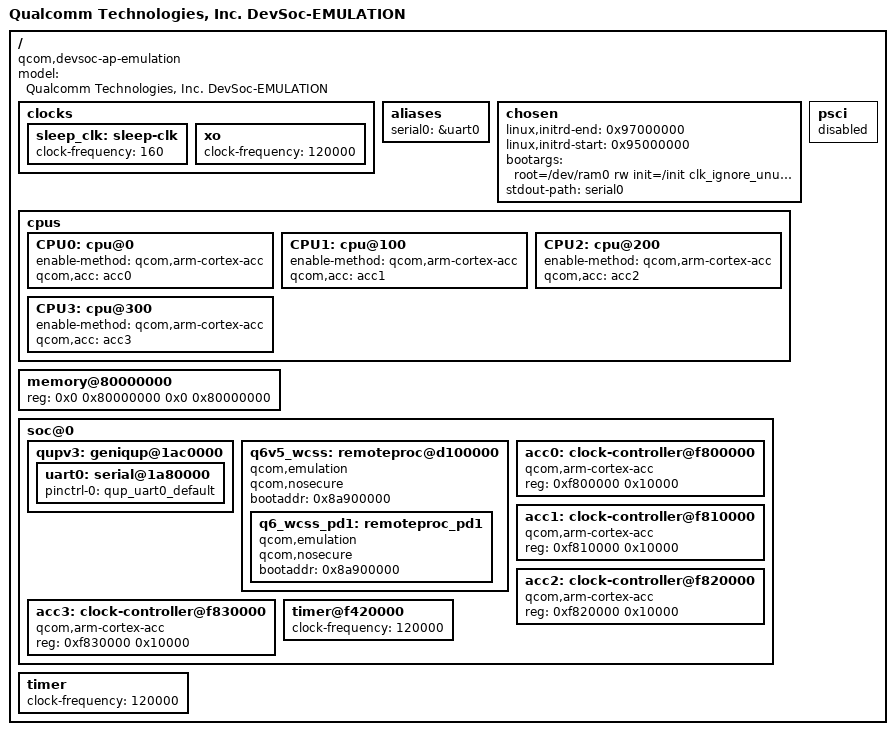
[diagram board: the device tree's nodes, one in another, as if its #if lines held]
// SPDX-License-Identifier: (GPL-2.0+ OR BSD-3-Clause)
/*
 * Dev SoC Emulation SSOC device tree source
 *
 * Copyright (c) 2020-2021 The Linux Foundation. All rights reserved.
 * Copyright (c) 2022-2023 Qualcomm Innovation Center, Inc. All rights reserved.
 */

/dts-v1/;

#include "devsoc.dtsi"

/ {
	model = "Qualcomm Technologies, Inc. DevSoc-EMULATION";
	compatible = "qcom,devsoc-ap-emulation", "qcom,devsoc";

	/*Timer freq for rumi = timer freq / 200*/
	clocks {
		sleep_clk: sleep-clk {
			clock-frequency = <160>;
		};

		xo: xo {
			clock-frequency = <120000>;
		};
	};

	aliases {
		serial0 = &uart0;
	};

	chosen {
		linux,initrd-end = <0x97000000>;
		linux,initrd-start = <0x95000000>;
		bootargs = "root=/dev/ram0 rw init=/init clk_ignore_unused maxcpus=2";
		stdout-path = "serial0";
	};

	cpus: cpus {
		CPU0: cpu@0 {
			enable-method = "qcom,arm-cortex-acc";
			qcom,acc = <&acc0>;
		};

		CPU1: cpu@100 {
			enable-method = "qcom,arm-cortex-acc";
			qcom,acc = <&acc1>;
		};

		CPU2: cpu@200 {
			enable-method = "qcom,arm-cortex-acc";
			qcom,acc = <&acc2>;
		};

		CPU3: cpu@300 {
			enable-method = "qcom,arm-cortex-acc";
			qcom,acc = <&acc3>;
		};
	};

	memory@80000000 {
		reg = <0x0 0x80000000 0x0 0x80000000>;
	};

	soc@0 {
		qupv3: geniqup@1ac0000 {
			status = "okay";

			uart0: serial@1a80000 {
				pinctrl-0 = <&qup_uart0_default>;
				pinctrl-names = "default";
				status = "okay";
			};
		};

#ifdef __QCOM_NON_SECURE_PIL__
		q6v5_wcss: remoteproc@d100000 {
			qcom,emulation;
			qcom,nosecure;
			bootaddr = <0x8a900000>;
			q6_wcss_pd1: remoteproc_pd1 {
				qcom,emulation;
				qcom,nosecure;
				bootaddr = <0x8a900000>;
			};
		};
#endif

		acc0: clock-controller@f800000 {
			compatible = "qcom,arm-cortex-acc";
			reg = <0xf800000 0x10000>;
		};

		acc1: clock-controller@f810000 {
			compatible = "qcom,arm-cortex-acc";
			reg = <0xf810000 0x10000>;
		};

		acc2:clock-controller@f820000 {
			compatible = "qcom,arm-cortex-acc";
			reg = <0xf820000 0x10000>;
		};

		acc3:clock-controller@f830000 {
			compatible = "qcom,arm-cortex-acc";
			reg = <0xf830000 0x10000>;
		};

		/* Timer freq for rumi = timer freq / 200 */
		timer@f420000 {
			clock-frequency = <120000>;
		};
	};

	/* Timer freq for rumi = timer freq / 200 */
	timer {
		clock-frequency = <120000>;
	};

	psci {
		status = "disabled";
	};
};
